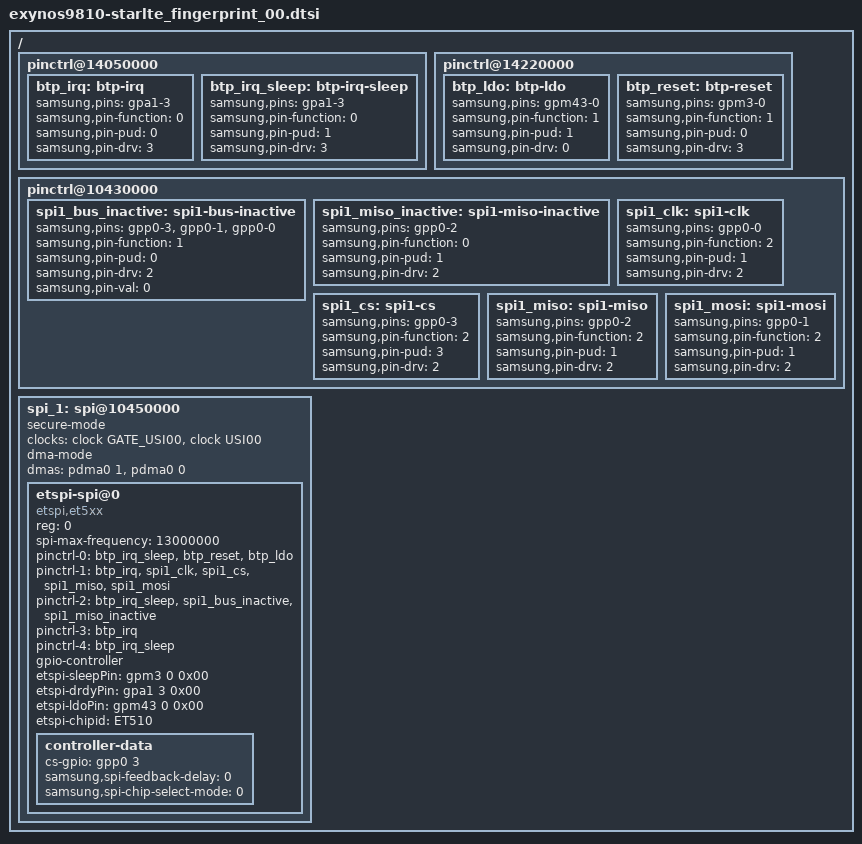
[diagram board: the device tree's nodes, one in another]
/*
 * Copyright (c) 2012-2013, The Linux Foundation. All rights reserved.
 *
 * This program is free software; you can redistribute it and/or modify
 * it under the terms of the GNU General Public License version 2 and
 * only version 2 as published by the Free Software Foundation.
 *
 * This program is distributed in the hope that it will be useful,
 * but WITHOUT ANY WARRANTY; without even the implied warranty of
 * MERCHANTABILITY or FITNESS FOR A PARTICULAR PURPOSE.  See the
 * GNU General Public License for more details.
 */

/ {
	pinctrl@14050000 {
		btp_irq: btp-irq {
			samsung,pins = "gpa1-3";
			samsung,pin-function = <0>;
			samsung,pin-pud = <0>;
			samsung,pin-drv = <3>;
		};
		btp_irq_sleep: btp-irq-sleep {
			samsung,pins = "gpa1-3";
			samsung,pin-function = <0>;
			samsung,pin-pud = <1>;
			samsung,pin-drv = <3>;
		};
	};

	pinctrl@14220000 {
		btp_ldo: btp-ldo {
			samsung,pins = "gpm43-0";
			samsung,pin-function = <1>;
			samsung,pin-pud = <1>;
			samsung,pin-drv = <0>;
		};
		btp_reset: btp-reset {
			samsung,pins = "gpm3-0";
			samsung,pin-function = <1>;
			samsung,pin-pud = <0>;
			samsung,pin-drv = <3>;
		};
	};

	pinctrl@10430000 {
		/* SPI_FP */
		spi1_bus_inactive: spi1-bus-inactive {
			samsung,pins = "gpp0-3", "gpp0-1", "gpp0-0";
			samsung,pin-function = <1>;
			samsung,pin-pud = <0>;
			samsung,pin-drv = <2>;
			samsung,pin-val = <0>;
		};
		spi1_miso_inactive: spi1-miso-inactive {
			samsung,pins = "gpp0-2";
			samsung,pin-function = <0>;
			samsung,pin-pud = <1>;
			samsung,pin-drv = <2>;
		};
		spi1_clk: spi1-clk {
			samsung,pins = "gpp0-0";
			samsung,pin-function = <2>;
			samsung,pin-pud = <1>;
			samsung,pin-drv = <2>;
		};
		spi1_cs: spi1-cs {
			samsung,pins = "gpp0-3";
			samsung,pin-function = <2>;
			samsung,pin-pud = <3>;
			samsung,pin-drv = <2>;
		};
		spi1_miso: spi1-miso {
			samsung,pins = "gpp0-2";
			samsung,pin-function = <2>;
			samsung,pin-pud = <1>;
			samsung,pin-drv = <2>;
		};
		spi1_mosi: spi1-mosi {
			samsung,pins = "gpp0-1";
			samsung,pin-function = <2>;
			samsung,pin-pud = <1>;
			samsung,pin-drv = <2>;
		};
	};

	/* SPI USI_PERIC0_USI00_SPI */
	spi_1: spi@10450000 {
		status = "okay";
		secure-mode;
		#address-cells = <1>;
		#size-cells = <0>;
		clocks = <&clock GATE_USI00>, <&clock USI00>;
		clock-names = "spi", "spi_busclk0";

		/delete-property/ pinctrl-names;
		/delete-property/ pinctrl-0;
		dma-mode;
		dmas = <&pdma0 1 &pdma0 0>;

		etspi-spi@0 {
			compatible = "etspi,et5xx";
			reg = <0>;
			spi-max-frequency = <13000000>;
			pinctrl-names = "default", "pins_poweron", "pins_poweroff"
							, "pins_poweron_tz", "pins_poweroff_tz";
			pinctrl-0 = <&btp_irq_sleep &btp_reset &btp_ldo>;
			pinctrl-1 = <&btp_irq &spi1_clk &spi1_cs &spi1_miso &spi1_mosi>;
			pinctrl-2 = <&btp_irq_sleep &spi1_bus_inactive &spi1_miso_inactive>;
			pinctrl-3 = <&btp_irq>;
			pinctrl-4 = <&btp_irq_sleep>;

			gpio-controller;
			#gpio-cells = <2>;

			etspi-sleepPin = <&gpm3 0 0x00>;
			etspi-drdyPin = <&gpa1 3 0x00>;
			etspi-ldoPin = <&gpm43 0 0x00>;
			etspi-chipid = "ET510";

			controller-data {
				cs-gpio = <&gpp0 3 0>;
				samsung,spi-feedback-delay = <0>;
				samsung,spi-chip-select-mode = <0>;
			};
		};
	};
};
